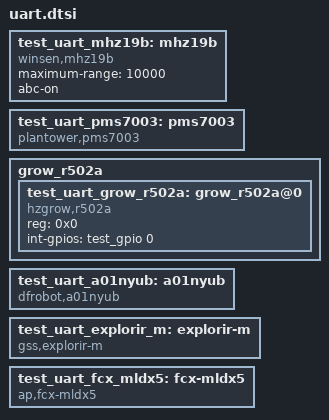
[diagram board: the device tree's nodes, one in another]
/*
 * Copyright (c) 2021, G-Technologies Sdn. Bhd.
 * Copyright (c) 2021 Linumiz.
 *
 * SPDX-License-Identifier: Apache-2.0
 *
 * Application overlay for uart devices
 */

test_uart_mhz19b: mhz19b {
	compatible = "winsen,mhz19b";
	maximum-range = <10000>;
	abc-on;
};

test_uart_pms7003: pms7003 {
	compatible = "plantower,pms7003";
};

grow_r502a {
	#address-cells=<1>;
	#size-cells=<0>;
	test_uart_grow_r502a: grow_r502a@0 {
		compatible = "hzgrow,r502a";
		reg = <0x0>;
		int-gpios = <&test_gpio 0 0>;
	};
};

test_uart_a01nyub: a01nyub {
	compatible = "dfrobot,a01nyub";
};

test_uart_explorir_m: explorir-m {
	compatible = "gss,explorir-m";
};

test_uart_fcx_mldx5: fcx-mldx5 {
	compatible = "ap,fcx-mldx5";
};
